# ESP32S31_RADIO register map
Vendor: Espressif; Series: ESP32-S31; File version: 3.52
Registers are 32-bit, read-write, no defined reset value unless marked. A register's access mark holds for its fields unless they carry their own. Offsets are from the block's base; [hi:lo] are bit positions.

## BLUETOOTH_SCHEDULER_INTERRUPT_RUNTIME — Scheduler words and the MAC diagnostic-signal pair transferred with BLUETOOTH_INTERRUPT_BANK to the primary hard handler. The source-124 reference gate samples scheduler BUSY through the diagnostic pair and can write a complete zero image to SCHEDULER_REFERENCE; the later deferred-work observation reads SCHEDULER_STATE. Task-side scheduler transactions borrow this owner for their own BUSY samples, which serializes every selector write with its value reads. Keeping this sparse physical view outside the task-side controller partition prevents either owner from manufacturing an MMIO alias.
Base 0x20101000
0x78 SCHEDULER_REFERENCE — Project-assigned name. The source-124 handler can publish the complete zero image when bank-one source 3 observes an idle scheduler through the diagnostic BUSY sample. Other scheduler users compare bits 0..19 or publish complete images; upper encoding remains unknown.
  [19:0] VALUE_LOW_20 — Project-assigned name.
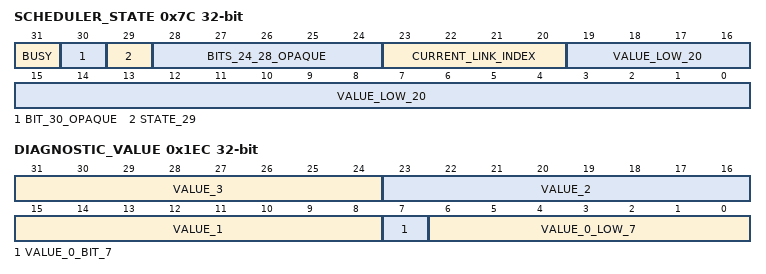
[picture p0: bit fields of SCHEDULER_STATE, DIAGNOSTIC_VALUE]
0x7C SCHEDULER_STATE — Project-assigned name. The source-124 handler reads this shared scheduler state before publishing deferred work. Its deferred-work predicate requires both STATE_29 and BUSY. The complete current-link-index leaf returns bits 23:20. Command transactions and the reference gate sample BUSY through DIAGNOSTIC_VALUE instead; other complete users consume or publish the low 20 and low 30 bits.
  [31] BUSY — Project-assigned name.
  [30] BIT_30_OPAQUE — Opaque: meaning not established.
  [29] STATE_29 — Project-assigned name. Positional state sampled together with BUSY by the complete source-124 deferred-work predicate. Its independent hardware meaning remains unqualified.
  [28:24] BITS_24_28_OPAQUE — Opaque: meaning not established.
  [23:20] CURRENT_LINK_INDEX — Project-assigned name. Zero-based current scheduler hardware-list index returned by the complete current-link-index leaf.
  [19:0] VALUE_LOW_20 — Project-assigned name.
0x1E8 DIAGNOSTIC_SELECT wo — Project-assigned name. Bluetooth MAC diagnostic-signal selector. Each byte lane selects one eight-bit diagnostic signal returned in the same lane of DIAGNOSTIC_VALUE. Scheduler command paths and the source-124 reference gate publish the complete SCHEDULER_STATUS image before sampling scheduler BUSY.
  [31:0] SELECTION — Project-assigned name. Complete observed selector images; only the images used by reviewed scheduler transactions are named.
    on write: 56=SCHEDULER_STATUS (Lane zero selects the scheduler status signal; lanes one to three select signal zero.); 0xC01=EXECUTION_MODIFY_PROGRESS (Lane zero selects signal 1 and lane one signal 12. Execution modify repeats its request while lane-zero bits 2:0 hold 2, or hold 3 with lane-one bits 5:4 equal to 1.); 7=EXECUTION_MODIFY_SETTLE (Lane zero selects signal 7; lanes one to three select signal zero. Execution modify completes once the complete value differs from 9.)
0x1EC DIAGNOSTIC_VALUE ro — Project-assigned name. Diagnostic-signal values for the four DIAGNOSTIC_SELECT lanes. The value crosses from the MAC clock domain: readers accept a sample only when two consecutive complete reads are equal.
  [31:24] VALUE_3 — Project-assigned name.
  [23:16] VALUE_2 — Project-assigned name.
  [15:8] VALUE_1 — Project-assigned name.
  [7] VALUE_0_BIT_7 — Project-assigned name. Bit 7 of the lane-zero signal. With SCHEDULER_STATUS selected it is scheduler BUSY, with the polarity of SCHEDULER_STATE.BUSY.
  [6:0] VALUE_0_LOW_7 — Project-assigned name.

## BLUETOOTH_RESET_IDLE_STATUS_0 — One independently bounded Bluetooth baseband reset-idle status word. The complete bbmac_idle_for_swrst leaf proves the exact predicate but neither address adjacency nor the function name proves a wider physical block.
Base 0x20101550
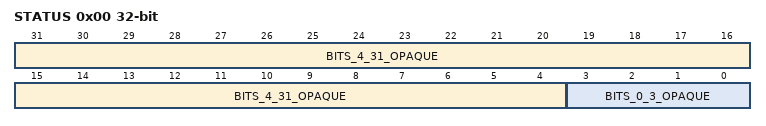
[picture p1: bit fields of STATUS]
0x00 STATUS ro — Project-assigned name. bbmac_idle_for_swrst requires the observed low four-bit field to be zero before reporting idle.
  [31:4] BITS_4_31_OPAQUE — Opaque: meaning not established. Observed source use; the individual hardware meaning is unknown.
  [3:0] BITS_0_3_OPAQUE — Opaque: meaning not established. The reset-idle predicate fails when this exact field is nonzero.
